# A31G11x_series register map
Vendor: ABOV Semiconductor Co., Ltd.; Series: A31G11x_series; File version: 1.0
CPU: CM0PLUS r0p1, little endian, no MPU, no FPU, VTOR, 2 interrupt priority bits
Registers are 32-bit, read-write, reset 0x0 unless marked. A register's access mark holds for its fields unless they carry their own. Offsets are from the block's base; [hi:lo] are bit positions; {n}, {i} and the like mark numbered series.

## T20 — TIMER COUNTER 20/21
Base 0x40002500
Same registers: T21 0x40002600
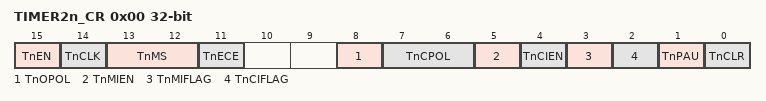
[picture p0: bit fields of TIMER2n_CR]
0x00 TIMER2n_CR — Timer/Counter 2n Control Register
  [15] TnEN — Timer n Operation Enable bit
  [14] TnCLK — Timer n Clock Selection bit (Note: This bit should be changed during TnEN bit is "0b".)
  [13:12] TnMS — Timer n Operation Mode Selection bits (Note: These bits should be changed during TnEN bit is "0b".)
  [11] TnECE — Timer n External Clock Edge Selection bit
  [8] TnOPOL — TnOUT Polarity Selection bit
  [7:6] TnCPOL — Timer n Capture Polarity Selection bits
  [5] TnMIEN — Timer n Match Interrupt Enable bit
  [4] TnCIEN — Timer n Capture Interrupt Enable bit
  [3] TnMIFLAG — Timer n Match Interrupt Flag bit
  [2] TnCIFLAG — Timer n Capture Interrupt Flag bit
  [1] TnPAU — Timer n Counter Temporary Pause Control bit
  [0] TnCLR — Timer n Counter and Prescaler Clear bit
0x04 TIMER2n_ADR reset 0xFFFFFFFF — Timer/Counter 2n A Data Register
  [31:0] ADATA — Timer/Counter n A Data bits. The range is 0x00000000 to 0xFFFFFFFF. Note: Do not write "00000000H" in the TnADR register when PPG mode.
0x08 TIMER2n_BDR reset 0xFFFFFFFF — Timer/Counter 2n B Data Register
  [31:0] BDATA — Timer/Counter n B Data bits. The range is 0x00000000 to 0xFFFFFFFF.
0x0C TIMER2n_CAPDR ro — Timer/Counter 2n Capture Data Register
  [31:0] CAPD — Timer/Counter n Capture Data bits.
0x10 TIMER2n_PREDR reset 0xFFF — Timer/Counter 2n Prescaler Data Register
  [11:0] PRED — Timer/Counter n Prescaler Data bits.P
0x14 TIMER2n_CNT ro — Timer/Counter 2n Counter Register
  [31:0] CNT — Timer/Counter n Counter bits.

## ADC — 12-BIT A/D CONVERTER
Base 0x40003000
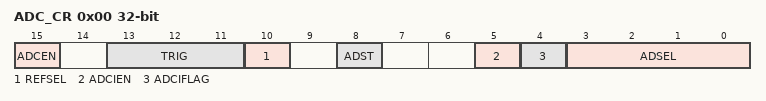
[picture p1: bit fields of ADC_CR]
0x00 ADC_CR — A/D Converter Control Register
  [15] ADCEN — A/DC Module Enable bit (The A/DC is automatically disabled at power down mode)
    0=DISABLE_ADC (Disable A/DC module operation); 1=ENABLE_ADC (Enable A/DC module operation)
  [13:11] TRIG — A/DC Trigger Signal Selection bits
    0=ADST; 1=T10_A_MATCH (Timer 10 A-match signal); 2=T11_A_MATCH (Timer 11 A-match signal); 3=T12_A_MATCH (Timer 12 A-match signal); 4=T30_SIGNAL (A/DC trigger signal from timer 30)
  [10] REFSEL — A/DC Reference Selection bit
    0=VDD (Select analog power (VDD)); 1=AVREF (Select external reference (AVREF))
  [8] ADST — A/DC Conversion Start bit. This bit is automatically cleared to "0b" after operation
    0=NONE (No effect); 1=START_AD_CONVERSION (Trigger signal generation for conversion start)
  [5] ADCIEN — A/DC Interrupt Enable bit
    0=DISABLE_ADC_INT (Disable A/DC interrupt); 1=ENABLE_ADC_INT (Enable A/DC interrupt)
  [4] ADCIFLAG — A/DC Interrupt Flag bit
    0=ADC_IF_CLR (No request occurred); 1=ADC_IF_SET (Request occurred, This bit is cleared to '0' when write '1'.)
  [3:0] ADSEL — A/D Converter Channel Selection bits
    {v}=AN{v} (v=0..10); 15=VDD18 (VDD15)
0x04 ADC_DR ro — A/D Converter Data Register
  [11:0] ADDATA — A/D Converter Result Data bits
0x08 ADC_PREDR reset 0xF — A/D Converter Prescaler Data Register
  [4:0] PRED — A/D Converter Prescaler Data bits.

## UART0
Base 0x40004000
Same registers: UART1 0x40004100
0x00 UARTn_RBR ro — UARTn Receive Data Buffer Register
  [7:0] DATA rw
0x00 UARTn_THR wo (alternate view of UARTnRBR) — UARTn Transmit Data Hold Register
  [7:0] DATA rw
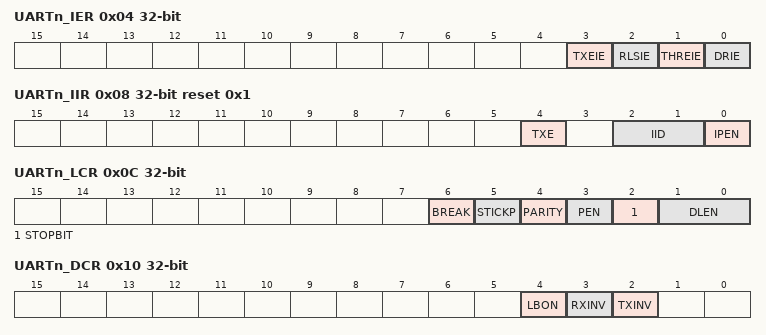
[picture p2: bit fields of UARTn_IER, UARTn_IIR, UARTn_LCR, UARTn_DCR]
0x04 UARTn_IER — UARTn Interrupt Enable Register
  [3] TXEIE — Transmit Empty Interrupt Enable bit
  [2] RLSIE — Receiver Line Status Interrupt Enable bit
  [1] THREIE — Transmit Holding Register Empty Interrupt Enable bit
  [0] DRIE — Data Receive Interrupt Enable bit
0x08 UARTn_IIR ro reset 0x1 — UARTn Interrupt ID Register
  [4] TXE — Transmit Complete Interrupt Source ID bit
  [2:1] IID — UARTn Interrupt ID bits. Note: The UARTn supports 3-priority interrupt generation and the interrupt source ID register shows one interrupt source which has highest priority among pending interrupts. The priority is defined as below. - Receive line status interrupt - Receive data ready interrupt and Character timeout interrupt - Transmit hold register empty interrupt
  [0] IPEN — Interrupt Pending bit
0x0C UARTn_LCR — UARTn Line Control Register
  [6] BREAK — Transfer Break Control bit. The TXDn pin will be driven at low state in order to notice
  [5] STICKP — Force Parity bit. This bit is effective when the PEN bit is set to "1b"
  [4] PARITY — Parity Mode and Parity Stuck Selection bit
  [3] PEN — Parity Bit Transfer Enable bit
  [2] STOPBIT — Stop Bit Length Selection bit
  [1:0] DLEN — Data Length Selection bits
0x10 UARTn_DCR — UARTn Data Control Register
  [4] LBON — Local Loopback Test Mode Enable bit
  [3] RXINV — Receive Data Inversion Selection bit
  [2] TXINV — Transmit Data Inversion Selection bit
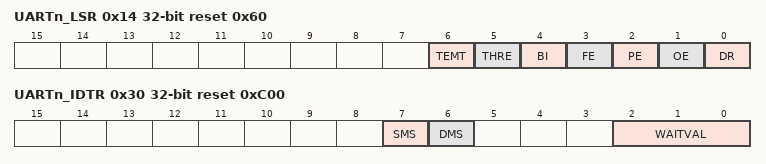
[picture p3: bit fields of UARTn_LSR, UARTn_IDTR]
0x14 UARTn_LSR ro reset 0x60 — UARTn Line Status Register
  [6] TEMT — Transmit Empty bit
  [5] THRE — Transmit Holding Empty bit. Note: This bit will be set to "1b" when it starts transmit.
  [4] BI — Break Condition Indication bit
  [3] FE — Frame Error Indicator bit
  [2] PE — Parity Error Indicator bit
  [1] OE — Overrun Error Indicator bit
  [0] DR — Data Receive Indicator bit
0x20 UARTn_BDR — UARTn Baud Rate Divisor Latch Register
  [15:0] BDR — Baud Rate Divider Latch Value. Baud rate = fUARTnCLK/(16 x BDR[15:0] x 2). Note: The UART block won't work if the BDR[15:0] == 0x0000.
0x24 UARTn_BFR — UARTn Baud Rate Fractional Counter Value
  [7:0] BFR — Fraction Counter value. 0 = Disable fraction counter N = Fraction compensation mode is operating. Fraction counter is incremented by FCNT. FCNT = Float * 256 Note: 8-bit fractional counter will count up by FCNT value every (baud rate)/16 period and whenever fractional counter overflow is happen, the divisor value will increment by 1. So this period will be compensated. Then next period, the divisor value will return to original set value.
    0=DISABLE_FRACTION_COUNTER
0x30 UARTn_IDTR reset 0xC00 — UARTn Inter-frame Delay Time Register
  [7] SMS — Start Bit Multi Sampling Enable bit
  [6] DMS — Data Bit Multi sampling enable
  [2:0] WAITVAL — Wait Time Value. Dummy delay can be inserted between 2 Continuous Transmits. Wait Time = WAITVAL[2:0]/(Baud Rate)
